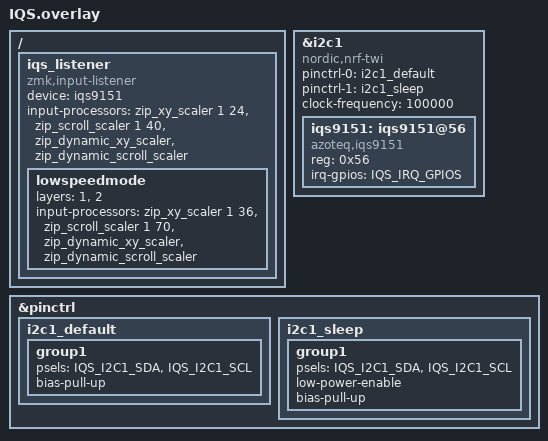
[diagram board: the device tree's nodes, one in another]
&i2c1 {
    status = "okay";
    compatible = "nordic,nrf-twi";
    pinctrl-0 = <&i2c1_default>;
    pinctrl-1 = <&i2c1_sleep>;
    pinctrl-names = "default", "sleep";
    clock-frequency = <100000>;

    iqs9151: iqs9151@56 {
        compatible = "azoteq,iqs9151";
        reg = <0x56>;
        status = "okay";
        irq-gpios = IQS_IRQ_GPIOS;
    };
};

&pinctrl {
    i2c1_default: i2c1_default {
        group1 {
            psels = <IQS_I2C1_SDA>,
                    <IQS_I2C1_SCL>;
            bias-pull-up;
        };
    };

    i2c1_sleep: i2c1_sleep {
        group1 {
            psels = <IQS_I2C1_SDA>,
                    <IQS_I2C1_SCL>;
            low-power-enable;
            bias-pull-up;
        };
    };
};

/ {
    iqs_listener: iqs_listener {
        compatible = "zmk,input-listener";
        status = "okay";
        device = <&iqs9151>;
        input-processors = <&zip_xy_scaler 1 24>,
                           <&zip_scroll_scaler 1 40>,
                           <&zip_dynamic_xy_scaler>,
                           <&zip_dynamic_scroll_scaler>;

        lowspeedmode {
            layers = <1>, <2>;
            input-processors = <&zip_xy_scaler 1 36>,
                               <&zip_scroll_scaler 1 70>,
                               <&zip_dynamic_xy_scaler>,
                               <&zip_dynamic_scroll_scaler>;
        };
    };
};
